AUTOSAR XML (schema 00044)
package /ComponentTypes
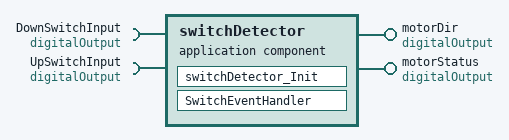
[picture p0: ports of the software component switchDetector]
  application sw component type switchDetector
    require port DownSwitchInput: nonqueued-receiver-com-spec{data-element=outputStatus, filter=data-filter-type=ALWAYS}, required-interface=digitalOutput
    require port UpSwitchInput: nonqueued-receiver-com-spec{data-element=outputStatus, filter=data-filter-type=ALWAYS}, required-interface=digitalOutput
    provide port motorDir: nonqueued-sender-com-spec=outputStatus, provided-interface=digitalOutput
    provide port motorStatus: nonqueued-sender-com-spec=outputStatus, provided-interface=digitalOutput
    behavior switchDetector_InternalBehavior
      init event switchDetector_InitEvent: start-on-event=switchDetector_Init
      explicit-inter-runnable-variables:
        data windowPosition: type=uint16, init-value=1
      runnable switchDetector_Init
        data-send-points:
          access SEND_motorDir_outputStatus: accessed-variable=motorDir.outputStatus
          access SEND_motorStatus_outputStatus: accessed-variable=motorStatus.outputStatus
        written-local-variables:
          access WRITE_windowPosition: accessed-variable=windowPosition
      runnable SwitchEventHandler
        data-send-points:
          access SEND_motorDir_outputStatus: accessed-variable=motorDir.outputStatus
          access SEND_motorStatus_outputStatus: accessed-variable=motorStatus.outputStatus
        read-local-variables:
          access Read_windowPosition: accessed-variable=windowPosition
        written-local-variables:
          access WRITE_windowPosition: accessed-variable=windowPosition
  swc implementation switchDetector_Implementation: behavior=switchDetector_InternalBehavior
